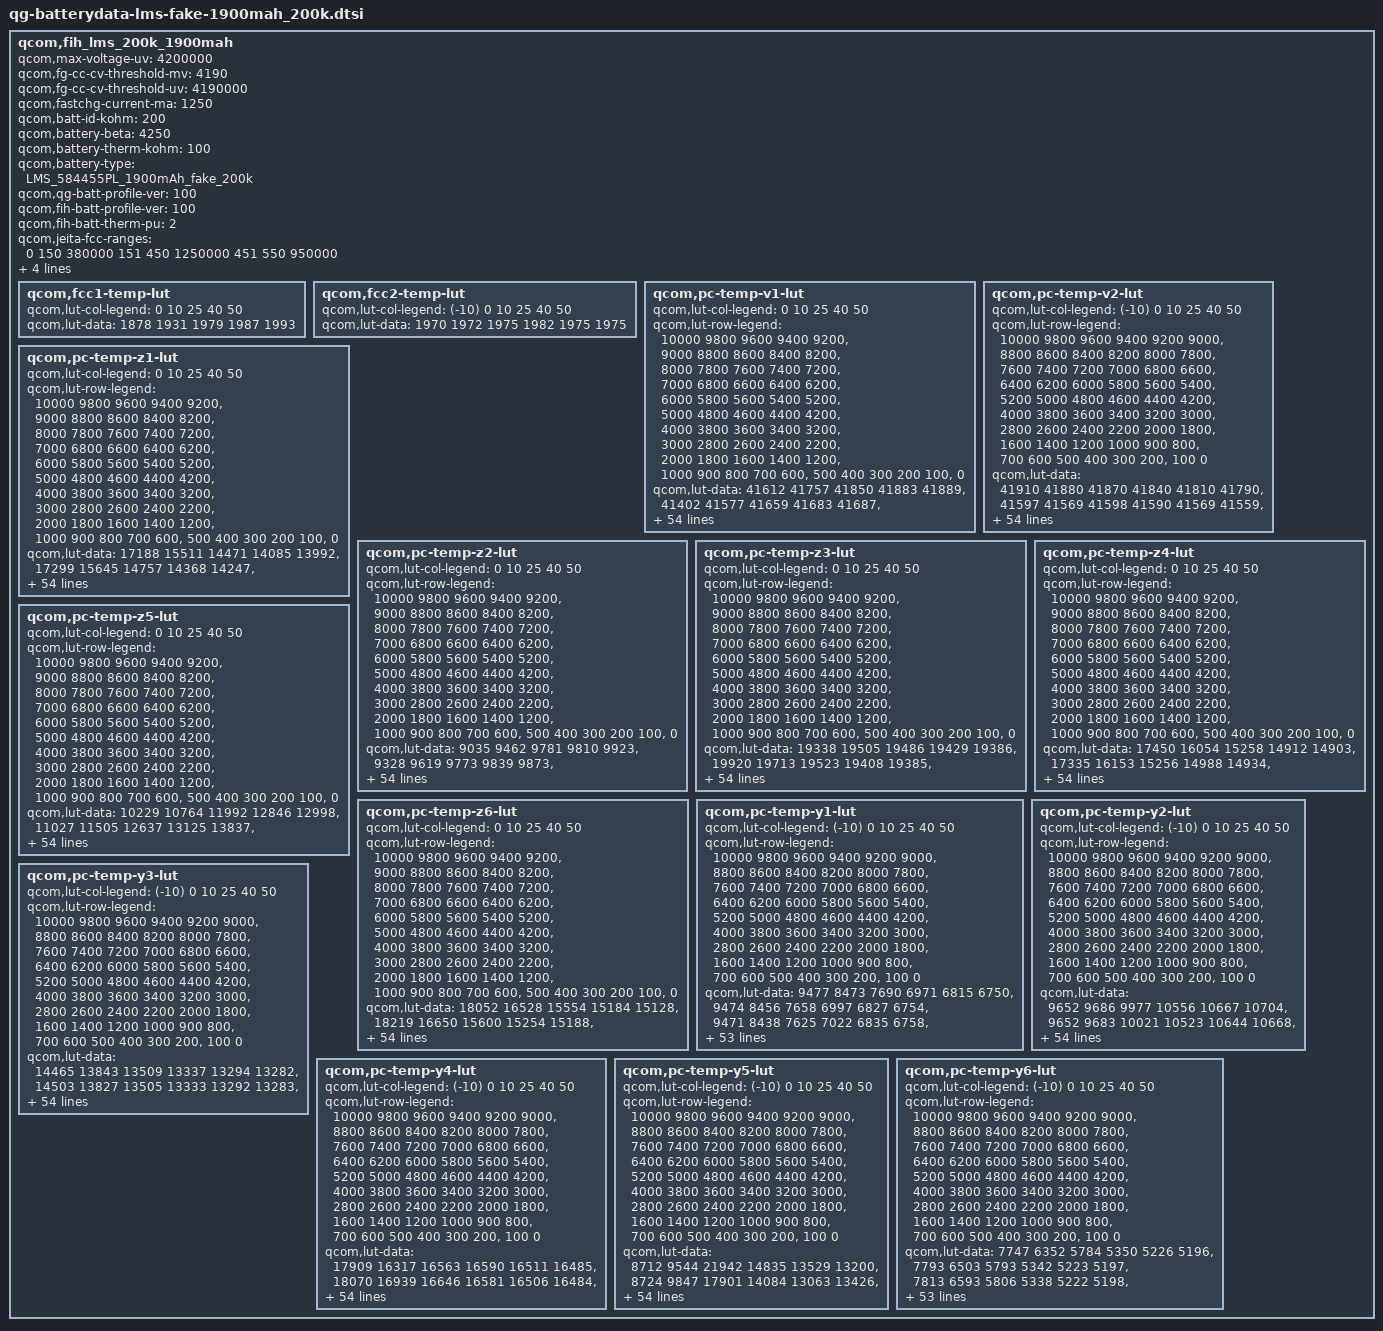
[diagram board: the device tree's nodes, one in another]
qcom,fih_lms_200k_1900mah {
	/* 3876802_FIH_LMS_VK_1900mAH_PMI632_FG_averaged_Master_Mar6th2019 */
	qcom,max-voltage-uv = <4200000>;
	qcom,fg-cc-cv-threshold-mv = <4190>;
	qcom,fg-cc-cv-threshold-uv = <4190000>;
	qcom,fastchg-current-ma = <1250>;
	qcom,batt-id-kohm = <200>;
	qcom,battery-beta = <4250>;
	qcom,battery-therm-kohm = <100>;
	qcom,battery-type =
		"LMS_584455PL_1900mAh_fake_200k";
	qcom,qg-batt-profile-ver = <100>;
	qcom,fih-batt-profile-ver = <100>;
	qcom,fih-batt-therm-pu = <2>; // pu1 = 30k, pu2 = 100k, pu3 = 400k

	qcom,jeita-fcc-ranges = <0   150   380000
				 151 450  1250000
				 451 550  950000>;
	qcom,jeita-fv-ranges =  <0   150  4200000
				 151 450  4200000
				 451 550  4000000>;

	qcom,jeita-soft-thresholds = <0x4621 0x20B8>;
	qcom,jeita-hard-thresholds = <0x58CD 0x181D>;

	qcom,fcc1-temp-lut {
		qcom,lut-col-legend = <0 10 25 40 50>;
		qcom,lut-data = <1878 1931 1979 1987 1993>;
	};

	qcom,fcc2-temp-lut {
		qcom,lut-col-legend = <(-10) 0 10 25 40 50>;
		qcom,lut-data = <1970 1972 1975 1982 1975 1975>;
	};

	qcom,pc-temp-v1-lut {
		qcom,lut-col-legend = <0 10 25 40 50>;
		qcom,lut-row-legend = <10000 9800 9600 9400 9200>,
			<9000 8800 8600 8400 8200>,
			<8000 7800 7600 7400 7200>,
			<7000 6800 6600 6400 6200>,
			<6000 5800 5600 5400 5200>,
			<5000 4800 4600 4400 4200>,
			<4000 3800 3600 3400 3200>,
			<3000 2800 2600 2400 2200>,
			<2000 1800 1600 1400 1200>,
			<1000 900 800 700 600>,
			<500 400 300 200 100>,
			<0>;
		qcom,lut-data = <41612 41757 41850 41883 41889>,
			<41402 41577 41659 41683 41687>,
			<41223 41381 41468 41482 41489>,
			<41089 41195 41272 41291 41301>,
			<40965 41046 41086 41097 41110>,
			<40763 40920 40920 40916 40923>,
			<40430 40750 40776 40753 40743>,
			<40145 40450 40605 40588 40567>,
			<39989 40158 40345 40399 40395>,
			<39869 40002 40096 40205 40226>,
			<39763 39892 39961 40042 40066>,
			<39673 39789 39865 39901 39910>,
			<39582 39692 39755 39763 39762>,
			<39478 39595 39625 39624 39620>,
			<39367 39486 39497 39491 39485>,
			<39262 39372 39380 39365 39358>,
			<39162 39267 39270 39245 39238>,
			<39066 39172 39165 39132 39124>,
			<38977 39077 39070 39032 39020>,
			<38892 38981 38952 38918 38906>,
			<38806 38879 38775 38759 38752>,
			<38719 38734 38595 38588 38581>,
			<38632 38516 38474 38451 38439>,
			<38544 38366 38377 38331 38313>,
			<38458 38313 38304 38240 38215>,
			<38379 38278 38247 38171 38142>,
			<38302 38251 38199 38114 38082>,
			<38241 38230 38154 38063 38028>,
			<38201 38210 38114 38018 37980>,
			<38172 38186 38078 37982 37939>,
			<38152 38163 38045 37953 37904>,
			<38137 38139 38018 37927 37876>,
			<38125 38113 37995 37904 37855>,
			<38113 38090 37973 37881 37835>,
			<38103 38073 37954 37858 37811>,
			<38093 38054 37935 37834 37780>,
			<38082 38032 37910 37804 37743>,
			<38069 38004 37876 37764 37698>,
			<38035 37961 37828 37712 37641>,
			<37952 37876 37753 37641 37568>,
			<37849 37766 37648 37548 37476>,
			<37720 37650 37532 37438 37368>,
			<37572 37515 37395 37305 37237>,
			<37408 37353 37247 37160 37095>,
			<37251 37211 37105 37022 36960>,
			<37109 37091 36981 36917 36860>,
			<37035 37015 36870 36845 36801>,
			<36935 36908 36691 36720 36705>,
			<36734 36601 36445 36519 36539>,
			<36281 36335 36138 36232 36261>,
			<35865 35926 35712 35810 35821>,
			<35262 35329 35133 35235 35226>,
			<34532 34619 34420 34536 34517>,
			<33625 33731 33523 33671 33641>,
			<32278 32491 32192 32472 32421>,
			<30000 30000 30000 30000 30000>;
	};

	qcom,pc-temp-v2-lut {
		qcom,lut-col-legend = <(-10) 0 10 25 40 50>;
		qcom,lut-row-legend = <10000 9800 9600 9400 9200 9000>,
			<8800 8600 8400 8200 8000 7800>,
			<7600 7400 7200 7000 6800 6600>,
			<6400 6200 6000 5800 5600 5400>,
			<5200 5000 4800 4600 4400 4200>,
			<4000 3800 3600 3400 3200 3000>,
			<2800 2600 2400 2200 2000 1800>,
			<1600 1400 1200 1000 900 800>,
			<700 600 500 400 300 200>,
			<100 0>;
		qcom,lut-data = <41910 41880 41870 41840 41810 41790>,
			<41597 41569 41598 41590 41569 41559>,
			<41330 41303 41353 41360 41345 41340>,
			<41127 41096 41144 41150 41138 41136>,
			<40971 40935 40963 40958 40946 40946>,
			<40779 40744 40780 40778 40763 40761>,
			<40487 40474 40596 40615 40592 40581>,
			<40178 40198 40402 40447 40423 40406>,
			<39929 39987 40167 40230 40247 40237>,
			<39708 39804 39912 39991 40071 40073>,
			<39524 39651 39741 39828 39911 39917>,
			<39375 39523 39635 39724 39768 39769>,
			<39234 39405 39537 39620 39631 39627>,
			<39083 39293 39432 39493 39493 39488>,
			<38933 39182 39324 39362 39361 39355>,
			<38782 39050 39199 39239 39237 39230>,
			<38630 38896 39056 39122 39118 39111>,
			<38499 38728 38903 39001 39001 38994>,
			<38394 38521 38729 38880 38890 38883>,
			<38301 38331 38557 38747 38772 38764>,
			<38214 38214 38407 38573 38607 38600>,
			<38133 38129 38272 38377 38409 38404>,
			<38057 38055 38158 38235 38262 38259>,
			<37987 37990 38060 38129 38154 38152>,
			<37921 37930 37984 38043 38067 38065>,
			<37859 37874 37933 37968 37994 37990>,
			<37801 37822 37892 37907 37932 37928>,
			<37742 37777 37860 37859 37878 37873>,
			<37683 37739 37832 37822 37829 37823>,
			<37627 37703 37807 37795 37791 37782>,
			<37574 37666 37782 37778 37762 37748>,
			<37522 37632 37759 37762 37737 37719>,
			<37471 37598 37738 37744 37714 37692>,
			<37418 37566 37716 37725 37692 37667>,
			<37365 37534 37693 37701 37661 37630>,
			<37310 37501 37665 37670 37614 37566>,
			<37250 37461 37629 37630 37556 37493>,
			<37180 37402 37573 37569 37492 37424>,
			<37100 37319 37495 37491 37418 37353>,
			<37009 37213 37400 37407 37345 37284>,
			<36905 37067 37279 37307 37271 37215>,
			<36797 36885 37139 37188 37168 37114>,
			<36683 36659 36968 37048 37037 36984>,
			<36575 36423 36745 36877 36886 36845>,
			<36471 36234 36522 36724 36760 36728>,
			<36349 36072 36320 36557 36674 36667>,
			<36269 35986 36186 36440 36589 36596>,
			<36168 35894 36028 36240 36429 36460>,
			<36020 35789 35855 35975 36185 36228>,
			<35788 35619 35631 35651 35854 35887>,
			<35402 35294 35272 35159 35387 35394>,
			<34808 34752 34708 34521 34780 34766>,
			<33991 34008 33971 33727 34053 34029>,
			<32892 32962 33011 32716 33144 33125>,
			<31287 31346 31633 31443 31990 31977>,
			<27080 26927 29600 27318 29739 29453>;
	};

	qcom,pc-temp-z1-lut {
		qcom,lut-col-legend = <0 10 25 40 50>;
		qcom,lut-row-legend = <10000 9800 9600 9400 9200>,
			<9000 8800 8600 8400 8200>,
			<8000 7800 7600 7400 7200>,
			<7000 6800 6600 6400 6200>,
			<6000 5800 5600 5400 5200>,
			<5000 4800 4600 4400 4200>,
			<4000 3800 3600 3400 3200>,
			<3000 2800 2600 2400 2200>,
			<2000 1800 1600 1400 1200>,
			<1000 900 800 700 600>,
			<500 400 300 200 100>,
			<0>;
		qcom,lut-data = <17188 15511 14471 14085 13992>,
			<17299 15645 14757 14368 14247>,
			<17367 15708 14803 14424 14306>,
			<17396 15762 14818 14447 14323>,
			<17415 15788 14837 14458 14348>,
			<17427 15805 14844 14470 14366>,
			<17437 15809 14847 14486 14376>,
			<17441 15791 14848 14499 14385>,
			<17423 15772 14847 14507 14398>,
			<17391 15774 14847 14513 14411>,
			<17384 15782 14855 14520 14420>,
			<17395 15789 14878 14527 14427>,
			<17412 15796 14894 14533 14433>,
			<17439 15805 14903 14541 14438>,
			<17473 15828 14911 14548 14442>,
			<17479 15862 14918 14553 14447>,
			<17450 15875 14925 14558 14454>,
			<17425 15879 14940 14564 14461>,
			<17456 15881 14966 14576 14468>,
			<17523 15872 14977 14585 14474>,
			<17539 15856 14969 14587 14481>,
			<17478 15858 14960 14588 14487>,
			<17421 15883 14962 14592 14493>,
			<17418 15898 14968 14603 14500>,
			<17419 15897 14978 14613 14506>,
			<17421 15895 14999 14624 14512>,
			<17424 15897 15015 14631 14518>,
			<17430 15906 15018 14631 14523>,
			<17459 15915 15020 14631 14529>,
			<17522 15922 15019 14634 14535>,
			<17545 15930 15015 14645 14542>,
			<17501 15939 15012 14652 14546>,
			<17453 15949 15014 14652 14548>,
			<17475 15963 15018 14652 14550>,
			<17558 15990 15034 14656 14553>,
			<17596 16015 15064 14666 14558>,
			<17573 16023 15071 14672 14562>,
			<17544 16028 15058 14674 14565>,
			<17558 16038 15048 14676 14568>,
			<17620 16078 15054 14680 14574>,
			<17653 16114 15064 14686 14581>,
			<17651 16120 15071 14696 14586>,
			<17647 16123 15076 14709 14589>,
			<17571 16147 15082 14710 14594>,
			<17552 16145 15094 14710 14601>,
			<17669 16126 15127 14723 14612>,
			<17558 16126 15140 14735 14620>,
			<17555 16147 15125 14745 14635>,
			<17671 16166 15128 14763 14660>,
			<17746 16216 15140 14798 14703>,
			<17639 16221 15194 14849 14778>,
			<17617 16271 15258 14900 14836>,
			<17753 16287 15255 14969 14902>,
			<17774 16314 15350 15049 14977>,
			<17774 16314 15350 15049 14977>,
			<17774 16314 15350 15049 14977>;
	};

	qcom,pc-temp-z2-lut {
		qcom,lut-col-legend = <0 10 25 40 50>;
		qcom,lut-row-legend = <10000 9800 9600 9400 9200>,
			<9000 8800 8600 8400 8200>,
			<8000 7800 7600 7400 7200>,
			<7000 6800 6600 6400 6200>,
			<6000 5800 5600 5400 5200>,
			<5000 4800 4600 4400 4200>,
			<4000 3800 3600 3400 3200>,
			<3000 2800 2600 2400 2200>,
			<2000 1800 1600 1400 1200>,
			<1000 900 800 700 600>,
			<500 400 300 200 100>,
			<0>;
		qcom,lut-data = <9035 9462 9781 9810 9923>,
			<9328 9619 9773 9839 9873>,
			<9463 9616 9773 9863 9945>,
			<9463 9612 9780 9914 9902>,
			<9462 9608 9782 9910 9902>,
			<9459 9605 9783 9904 9900>,
			<9448 9600 9783 9884 9875>,
			<9441 9591 9783 9870 9852>,
			<9443 9585 9780 9882 9861>,
			<9447 9585 9776 9900 9883>,
			<9448 9587 9776 9893 9901>,
			<9447 9589 9777 9854 9917>,
			<9445 9591 9782 9837 9924>,
			<9442 9595 9803 9851 9923>,
			<9439 9603 9826 9871 9921>,
			<9438 9618 9838 9890 9920>,
			<9440 9632 9848 9909 9918>,
			<9442 9646 9859 9912 9918>,
			<9446 9663 9869 9903 9921>,
			<9453 9691 9881 9898 9927>,
			<9463 9722 9901 9950 9999>,
			<9479 9733 9915 10025 10105>,
			<9497 9735 9909 10038 10118>,
			<9515 9739 9891 10042 10103>,
			<9532 9755 9880 10040 10078>,
			<9548 9773 9876 9997 10004>,
			<9564 9777 9872 9950 9929>,
			<9577 9777 9863 9930 9908>,
			<9583 9777 9854 9916 9896>,
			<9587 9771 9853 9915 9882>,
			<9591 9764 9858 9917 9864>,
			<9594 9764 9865 9922 9856>,
			<9598 9767 9880 9949 9875>,
			<9606 9771 9899 9986 9911>,
			<9619 9775 9914 10006 9942>,
			<9619 9780 9927 10021 9973>,
			<9435 9786 9936 10027 9995>,
			<9216 9792 9942 10029 10012>,
			<9200 9797 9948 10031 10023>,
			<9235 9802 9959 10042 10027>,
			<9253 9804 9970 10059 10030>,
			<9246 9799 9971 10064 10039>,
			<9237 9790 9968 10065 10058>,
			<9230 9795 9972 10058 10059>,
			<9214 9729 9991 10049 10052>,
			<9181 9597 9989 10098 10056>,
			<9167 9711 9969 10063 10048>,
			<9136 9494 9945 9986 10023>,
			<9247 9761 9906 9945 9949>,
			<9713 9821 9819 9861 9831>,
			<9717 9867 9661 9731 9683>,
			<9644 9833 9530 9608 9662>,
			<9565 9682 9442 9716 9713>,
			<9104 9519 9260 9774 9761>,
			<9104 9519 9260 9774 9761>,
			<9104 9519 9260 9774 9761>;
	};

	qcom,pc-temp-z3-lut {
		qcom,lut-col-legend = <0 10 25 40 50>;
		qcom,lut-row-legend = <10000 9800 9600 9400 9200>,
			<9000 8800 8600 8400 8200>,
			<8000 7800 7600 7400 7200>,
			<7000 6800 6600 6400 6200>,
			<6000 5800 5600 5400 5200>,
			<5000 4800 4600 4400 4200>,
			<4000 3800 3600 3400 3200>,
			<3000 2800 2600 2400 2200>,
			<2000 1800 1600 1400 1200>,
			<1000 900 800 700 600>,
			<500 400 300 200 100>,
			<0>;
		qcom,lut-data = <19338 19505 19486 19429 19386>,
			<19920 19713 19523 19408 19385>,
			<20217 19845 19573 19446 19399>,
			<20257 19912 19616 19460 19411>,
			<20279 19912 19635 19473 19418>,
			<20314 19898 19632 19475 19420>,
			<20364 19894 19613 19463 19419>,
			<20391 19928 19604 19455 19417>,
			<20367 19962 19621 19461 19414>,
			<20314 19946 19640 19471 19412>,
			<20262 19892 19625 19468 19410>,
			<20200 19845 19587 19450 19408>,
			<20158 19800 19575 19440 19407>,
			<20146 19773 19576 19438 19406>,
			<20140 19780 19576 19437 19405>,
			<20130 19793 19571 19437 19401>,
			<20118 19795 19562 19436 19394>,
			<20104 19781 19558 19435 19388>,
			<20082 19770 19557 19431 19382>,
			<20058 19772 19557 19429 19380>,
			<20053 19777 19580 19444 19392>,
			<20082 19787 19604 19466 19416>,
			<20115 19807 19598 19469 19432>,
			<20130 19819 19581 19470 19444>,
			<20141 19814 19579 19473 19454>,
			<20144 19805 19605 19496 19463>,
			<20140 19798 19624 19517 19468>,
			<20134 19791 19624 19515 19465>,
			<20124 19785 19623 19507 19457>,
			<20107 19780 19620 19497 19449>,
			<20086 19777 19610 19482 19441>,
			<20062 19777 19601 19470 19433>,
			<20033 19777 19592 19466 19423>,
			<20005 19777 19583 19462 19414>,
			<19976 19772 19575 19456 19405>,
			<19920 19763 19567 19447 19398>,
			<19637 19751 19561 19444 19396>,
			<19329 19734 19557 19444 19396>,
			<19287 19722 19552 19443 19396>,
			<19282 19716 19546 19434 19396>,
			<19281 19710 19539 19420 19395>,
			<19281 19696 19534 19417 19392>,
			<19282 19679 19530 19418 19385>,
			<19282 19670 19525 19418 19382>,
			<19283 19527 19509 19412 19381>,
			<19287 19267 19475 19390 19379>,
			<19289 19264 19497 19396 19380>,
			<19304 19268 19514 19406 19378>,
			<19685 19657 19559 19446 19398>,
			<19871 19687 19635 19496 19451>,
			<19864 19758 19687 19505 19455>,
			<19891 19895 19696 19496 19451>,
			<19897 20034 19695 19493 19443>,
			<19806 20187 19645 19490 19441>,
			<19806 20187 19645 19490 19441>,
			<19806 20187 19645 19490 19441>;
	};

	qcom,pc-temp-z4-lut {
		qcom,lut-col-legend = <0 10 25 40 50>;
		qcom,lut-row-legend = <10000 9800 9600 9400 9200>,
			<9000 8800 8600 8400 8200>,
			<8000 7800 7600 7400 7200>,
			<7000 6800 6600 6400 6200>,
			<6000 5800 5600 5400 5200>,
			<5000 4800 4600 4400 4200>,
			<4000 3800 3600 3400 3200>,
			<3000 2800 2600 2400 2200>,
			<2000 1800 1600 1400 1200>,
			<1000 900 800 700 600>,
			<500 400 300 200 100>,
			<0>;
		qcom,lut-data = <17450 16054 15258 14912 14903>,
			<17335 16153 15256 14988 14934>,
			<17183 16066 15316 14995 14916>,
			<16973 15915 15285 15026 14966>,
			<16727 15755 15205 14973 14929>,
			<16507 15562 15121 14927 14895>,
			<16303 15433 15021 14889 14869>,
			<16118 15364 14966 14857 14845>,
			<15950 15305 14951 14833 14821>,
			<15801 15230 14939 14815 14799>,
			<15700 15150 14908 14801 14783>,
			<15629 15099 14862 14791 14770>,
			<15569 15070 14836 14781 14760>,
			<15507 15044 14823 14771 14749>,
			<15451 15010 14815 14762 14740>,
			<15403 14974 14813 14753 14734>,
			<15362 14949 14811 14745 14729>,
			<15326 14932 14807 14740 14724>,
			<15295 14919 14800 14736 14721>,
			<15268 14908 14800 14734 14719>,
			<15234 14900 14888 14785 14761>,
			<15181 14934 14998 14867 14833>,
			<15143 15128 15046 14910 14859>,
			<15143 15250 15079 14939 14872>,
			<15151 15235 15079 14945 14874>,
			<15161 15202 15022 14894 14841>,
			<15182 15165 14963 14840 14802>,
			<15199 15119 14932 14825 14788>,
			<15196 15076 14908 14815 14780>,
			<15181 15039 14895 14808 14773>,
			<15165 15007 14886 14802 14767>,
			<15144 14978 14881 14796 14762>,
			<15124 14953 14878 14787 14753>,
			<15109 14932 14875 14779 14745>,
			<15097 14916 14871 14780 14747>,
			<15100 14903 14866 14783 14756>,
			<15345 14892 14865 14785 14761>,
			<15637 14882 14865 14786 14762>,
			<15663 14880 14865 14787 14763>,
			<15627 14882 14863 14791 14761>,
			<15596 14884 14858 14798 14755>,
			<15580 14880 14852 14796 14753>,
			<15561 14870 14841 14786 14751>,
			<15528 14850 14825 14782 14753>,
			<15393 14936 14795 14777 14753>,
			<15331 15122 14741 14737 14713>,
			<15334 15122 14741 14728 14705>,
			<15333 15148 14800 14742 14715>,
			<15112 15002 14878 14769 14738>,
			<15260 15137 14927 14805 14762>,
			<15444 15218 14914 14805 14770>,
			<15564 15204 14895 14798 14763>,
			<15790 15159 14881 14779 14753>,
			<16077 15088 14902 14767 14746>,
			<16077 15088 14902 14767 14746>,
			<16077 15088 14902 14767 14746>;
	};

	qcom,pc-temp-z5-lut {
		qcom,lut-col-legend = <0 10 25 40 50>;
		qcom,lut-row-legend = <10000 9800 9600 9400 9200>,
			<9000 8800 8600 8400 8200>,
			<8000 7800 7600 7400 7200>,
			<7000 6800 6600 6400 6200>,
			<6000 5800 5600 5400 5200>,
			<5000 4800 4600 4400 4200>,
			<4000 3800 3600 3400 3200>,
			<3000 2800 2600 2400 2200>,
			<2000 1800 1600 1400 1200>,
			<1000 900 800 700 600>,
			<500 400 300 200 100>,
			<0>;
		qcom,lut-data = <10229 10764 11992 12846 12998>,
			<11027 11505 12637 13125 13837>,
			<11488 12191 13112 14460 14710>,
			<11622 12664 13914 14404 14376>,
			<11708 12881 14382 15078 14768>,
			<11843 12999 14627 15264 15011>,
			<12040 13227 14753 15096 15082>,
			<12200 14011 14990 14971 15159>,
			<12297 14693 16132 15659 15380>,
			<12366 14650 17227 16729 15751>,
			<12361 14420 17014 16767 16123>,
			<12237 14196 16342 16298 16517>,
			<12142 13945 16261 16093 16926>,
			<12215 13788 17289 16349 17452>,
			<12395 14325 18128 16781 17849>,
			<12568 15560 18232 17320 17759>,
			<12740 16277 18299 17981 17434>,
			<12919 16581 18540 18375 17313>,
			<13072 16988 19265 18560 17296>,
			<13230 18228 20425 18840 17290>,
			<13569 20278 23731 20282 18628>,
			<14729 22498 26693 21975 20751>,
			<16268 25316 24531 20953 20282>,
			<17794 26723 18914 16942 17103>,
			<19438 24975 17328 15419 15676>,
			<20679 22036 17927 16807 16582>,
			<21720 20422 18764 18535 17817>,
			<22353 19292 19758 19664 18578>,
			<22164 18790 20849 20552 19210>,
			<21383 18673 21643 20634 19779>,
			<20512 18614 22312 20211 20359>,
			<19549 18883 22574 19975 20621>,
			<18513 19851 22611 20628 20503>,
			<17607 20553 22627 21429 20242>,
			<16771 20944 22497 21271 19794>,
			<15624 21172 22089 20503 19011>,
			<13118 21062 21636 19858 18386>,
			<10803 20674 21087 19440 17950>,
			<10514 20325 20516 18930 17571>,
			<10492 20088 19950 17700 17248>,
			<10486 19775 19426 16244 16937>,
			<10502 18760 19054 15936 16421>,
			<10514 17586 18786 15899 15620>,
			<10491 17776 18827 15806 14972>,
			<10535 15534 18776 15561 14751>,
			<10553 10709 18387 15598 16249>,
			<10546 10678 23110 16831 17594>,
			<10575 10702 21725 17703 17276>,
			<13916 25367 20486 19572 18102>,
			<25814 19934 20596 20127 20227>,
			<18380 17342 20042 19010 18132>,
			<14961 17048 18322 18014 17879>,
			<13112 16530 17702 19463 18227>,
			<11299 16430 14739 20603 19041>,
			<11299 16430 14739 20603 19041>,
			<11299 16430 14739 20603 19041>;
	};

	qcom,pc-temp-z6-lut {
		qcom,lut-col-legend = <0 10 25 40 50>;
		qcom,lut-row-legend = <10000 9800 9600 9400 9200>,
			<9000 8800 8600 8400 8200>,
			<8000 7800 7600 7400 7200>,
			<7000 6800 6600 6400 6200>,
			<6000 5800 5600 5400 5200>,
			<5000 4800 4600 4400 4200>,
			<4000 3800 3600 3400 3200>,
			<3000 2800 2600 2400 2200>,
			<2000 1800 1600 1400 1200>,
			<1000 900 800 700 600>,
			<500 400 300 200 100>,
			<0>;
		qcom,lut-data = <18052 16528 15554 15184 15128>,
			<18219 16650 15600 15254 15188>,
			<18277 16636 15655 15287 15200>,
			<18195 16606 15652 15306 15225>,
			<18033 16544 15635 15294 15218>,
			<17892 16422 15603 15278 15210>,
			<17757 16333 15539 15255 15200>,
			<17629 16286 15506 15239 15190>,
			<17509 16243 15501 15235 15181>,
			<17400 16185 15498 15233 15172>,
			<17319 16118 15478 15226 15165>,
			<17258 16068 15442 15213 15160>,
			<17208 16030 15429 15204 15155>,
			<17166 16003 15427 15200 15151>,
			<17131 15990 15426 15197 15146>,
			<17099 15981 15423 15194 15142>,
			<17070 15968 15420 15191 15137>,
			<17041 15948 15419 15189 15133>,
			<17003 15937 15418 15187 15129>,
			<16965 15937 15419 15186 15128>,
			<16951 15938 15471 15216 15153>,
			<16948 15957 15532 15264 15198>,
			<16947 16054 15550 15288 15222>,
			<16951 16115 15560 15305 15239>,
			<16961 16108 15561 15309 15244>,
			<16964 16093 15553 15302 15235>,
			<16964 16077 15543 15292 15224>,
			<16964 16056 15533 15285 15216>,
			<16959 16038 15524 15277 15209>,
			<16944 16024 15516 15269 15202>,
			<16926 16012 15509 15259 15196>,
			<16902 16003 15503 15251 15189>,
			<16876 15996 15498 15245 15179>,
			<16856 15991 15494 15240 15171>,
			<16839 15987 15490 15237 15169>,
			<16820 15983 15487 15235 15169>,
			<16795 15978 15486 15234 15169>,
			<16771 15973 15486 15235 15170>,
			<16754 15972 15486 15236 15172>,
			<16740 15981 15485 15235 15171>,
			<16733 15989 15482 15232 15169>,
			<16731 15987 15480 15229 15167>,
			<16730 15984 15479 15227 15164>,
			<16732 15988 15475 15227 15165>,
			<16707 15977 15462 15224 15165>,
			<16708 15956 15439 15200 15148>,
			<16722 15972 15458 15201 15147>,
			<16742 16002 15510 15220 15153>,
			<16833 16146 15588 15266 15183>,
			<17045 16242 15675 15329 15236>,
			<17133 16337 15731 15366 15266>,
			<17224 16427 15770 15390 15284>,
			<17338 16515 15814 15412 15299>,
			<17433 16604 15852 15437 15316>,
			<17433 16604 15852 15437 15316>,
			<17433 16604 15852 15437 15316>;
	};

	qcom,pc-temp-y1-lut {
		qcom,lut-col-legend = <(-10) 0 10 25 40 50>;
		qcom,lut-row-legend = <10000 9800 9600 9400 9200 9000>,
			<8800 8600 8400 8200 8000 7800>,
			<7600 7400 7200 7000 6800 6600>,
			<6400 6200 6000 5800 5600 5400>,
			<5200 5000 4800 4600 4400 4200>,
			<4000 3800 3600 3400 3200 3000>,
			<2800 2600 2400 2200 2000 1800>,
			<1600 1400 1200 1000 900 800>,
			<700 600 500 400 300 200>,
			<100 0>;
		qcom,lut-data = <9477 8473 7690 6971 6815 6750>,
			<9474 8456 7658 6997 6827 6754>,
			<9471 8438 7625 7022 6835 6758>,
			<9468 8421 7596 7042 6841 6762>,
			<9465 8407 7576 7055 6843 6765>,
			<9464 8398 7571 7059 6844 6767>,
			<9463 8391 7578 7051 6840 6769>,
			<9463 8387 7587 7044 6836 6771>,
			<9466 8388 7592 7048 6840 6771>,
			<9479 8393 7597 7058 6853 6771>,
			<9501 8405 7605 7064 6856 6771>,
			<9556 8444 7625 7066 6856 6772>,
			<9593 8471 7638 7069 6856 6774>,
			<9581 8450 7631 7080 6857 6776>,
			<9554 8414 7621 7092 6858 6778>,
			<9529 8402 7623 7092 6859 6779>,
			<9502 8397 7636 7090 6862 6781>,
			<9492 8396 7645 7090 6864 6784>,
			<9561 8413 7647 7095 6865 6787>,
			<9639 8432 7649 7101 6865 6790>,
			<9634 8430 7655 7098 6868 6792>,
			<9599 8421 7662 7091 6874 6793>,
			<9561 8416 7663 7090 6878 6795>,
			<9513 8413 7652 7093 6880 6800>,
			<9483 8411 7642 7097 6882 6805>,
			<9482 8435 7637 7106 6886 6808>,
			<9482 8477 7633 7117 6889 6811>,
			<9488 8477 7634 7125 6890 6814>,
			<9517 8440 7640 7131 6890 6816>,
			<9534 8420 7643 7134 6890 6819>,
			<9515 8447 7638 7136 6894 6825>,
			<9490 8478 7633 7139 6899 6830>,
			<9489 8471 7633 7142 6902 6831>,
			<9491 8445 7635 7145 6904 6832>,
			<9498 8439 7636 7143 6907 6832>,
			<9539 8470 7638 7130 6909 6833>,
			<9588 8497 7641 7122 6912 6835>,
			<9623 8482 7653 7128 6914 6839>,
			<9651 8455 7672 7137 6916 6844>,
			<9636 8450 7681 7139 6921 6847>,
			<9529 8458 7686 7141 6929 6849>,
			<9512 8470 7685 7146 6933 6854>,
			<9548 8489 7684 7154 6936 6864>,
			<9637 8543 7722 7192 6951 6871>,
			<9675 8576 7727 7175 6968 6879>,
			<9760 8592 7742 7189 6976 6893>,
			<9759 8599 7779 7192 6991 6908>,
			<9788 8621 7756 7211 7007 6934>,
			<9801 8628 7755 7221 7025 6962>,
			<9810 8642 7765 7220 7058 7005>,
			<9861 8705 7788 7262 7073 7022>,
			<9995 8728 7828 7261 7106 7043>,
			<10199 8763 7861 7329 7113 7070>,
			<10461 8929 7960 7367 7156 7107>,
			<10461 8929 7960 7367 7156 7107>,
			<10461 8929 7960 7367 7156 7107>;
	};

	qcom,pc-temp-y2-lut {
		qcom,lut-col-legend = <(-10) 0 10 25 40 50>;
		qcom,lut-row-legend = <10000 9800 9600 9400 9200 9000>,
			<8800 8600 8400 8200 8000 7800>,
			<7600 7400 7200 7000 6800 6600>,
			<6400 6200 6000 5800 5600 5400>,
			<5200 5000 4800 4600 4400 4200>,
			<4000 3800 3600 3400 3200 3000>,
			<2800 2600 2400 2200 2000 1800>,
			<1600 1400 1200 1000 900 800>,
			<700 600 500 400 300 200>,
			<100 0>;
		qcom,lut-data = <9652 9686 9977 10556 10667 10704>,
			<9652 9683 10021 10523 10644 10668>,
			<9653 9680 10072 10486 10619 10624>,
			<9653 9677 10121 10449 10593 10581>,
			<9653 9675 10161 10420 10566 10550>,
			<9653 9674 10183 10404 10537 10541>,
			<9653 9673 10197 10396 10499 10549>,
			<9653 9673 10205 10390 10471 10557>,
			<9653 9671 10204 10379 10472 10554>,
			<9653 9668 10201 10366 10475 10543>,
			<9653 9665 10204 10359 10476 10528>,
			<9653 9663 10241 10354 10470 10504>,
			<9653 9662 10287 10352 10466 10488>,
			<9653 9663 10323 10364 10472 10485>,
			<9654 9663 10360 10390 10487 10484>,
			<9654 9663 10402 10420 10501 10493>,
			<9654 9663 10451 10461 10517 10536>,
			<9654 9663 10470 10505 10541 10582>,
			<9654 9662 10461 10561 10602 10638>,
			<9654 9661 10446 10598 10661 10677>,
			<9654 9660 10428 10595 10678 10671>,
			<9654 9660 10406 10587 10687 10651>,
			<9654 9660 10393 10586 10693 10645>,
			<9654 9659 10387 10598 10696 10652>,
			<9653 9659 10382 10611 10700 10663>,
			<9654 9658 10375 10621 10709 10694>,
			<9654 9658 10369 10630 10719 10737>,
			<9654 9658 10365 10640 10724 10758>,
			<9654 9658 10362 10652 10727 10770>,
			<9654 9658 10357 10655 10732 10783>,
			<9654 9658 10349 10646 10775 10798>,
			<9653 9657 10341 10634 10819 10816>,
			<9653 9657 10339 10620 10808 10852>,
			<9653 9656 10338 10604 10771 10904>,
			<9653 9656 10336 10601 10754 10909>,
			<9653 9656 10333 10602 10752 10804>,
			<9653 9655 10325 10602 10748 10723>,
			<9653 9655 10123 10595 10733 10731>,
			<9653 9655 9788 10583 10714 10751>,
			<9653 9654 9710 10568 10716 10766>,
			<9653 9654 9698 10551 10739 10778>,
			<9653 9654 9685 10541 10727 10748>,
			<9653 9653 9673 10527 10699 10700>,
			<9652 9653 9666 10476 10690 10736>,
			<9653 9653 9663 10414 10648 10646>,
			<9652 9653 9661 10369 10588 10577>,
			<9652 9653 9660 10410 10574 10508>,
			<9652 9652 9659 10395 10494 10459>,
			<9651 9652 9658 10367 10504 10452>,
			<9651 9652 9657 10392 10508 10458>,
			<9650 9652 9657 10086 10537 10511>,
			<9649 9651 9656 10038 10556 10554>,
			<9648 9651 9655 9954 10576 10565>,
			<9647 9649 9654 10016 10540 10539>,
			<9647 9649 9654 10016 10540 10539>,
			<9647 9649 9654 10016 10540 10539>;
	};

	qcom,pc-temp-y3-lut {
		qcom,lut-col-legend = <(-10) 0 10 25 40 50>;
		qcom,lut-row-legend = <10000 9800 9600 9400 9200 9000>,
			<8800 8600 8400 8200 8000 7800>,
			<7600 7400 7200 7000 6800 6600>,
			<6400 6200 6000 5800 5600 5400>,
			<5200 5000 4800 4600 4400 4200>,
			<4000 3800 3600 3400 3200 3000>,
			<2800 2600 2400 2200 2000 1800>,
			<1600 1400 1200 1000 900 800>,
			<700 600 500 400 300 200>,
			<100 0>;
		qcom,lut-data = <14465 13843 13509 13337 13294 13282>,
			<14503 13827 13505 13333 13292 13283>,
			<14517 13797 13498 13331 13292 13285>,
			<14513 13764 13490 13332 13292 13286>,
			<14496 13739 13484 13334 13292 13287>,
			<14473 13731 13481 13337 13294 13288>,
			<14432 13733 13481 13344 13298 13289>,
			<14385 13735 13481 13349 13303 13290>,
			<14347 13716 13472 13346 13304 13290>,
			<14315 13672 13451 13340 13305 13290>,
			<14310 13659 13446 13340 13306 13291>,
			<14335 13665 13454 13350 13306 13296>,
			<14354 13674 13460 13359 13306 13300>,
			<14348 13690 13459 13362 13308 13300>,
			<14334 13708 13456 13365 13312 13300>,
			<14315 13712 13452 13365 13315 13302>,
			<14286 13714 13446 13364 13318 13305>,
			<14272 13714 13436 13362 13319 13307>,
			<14271 13680 13416 13360 13320 13307>,
			<14270 13642 13399 13358 13320 13307>,
			<14273 13643 13396 13350 13317 13304>,
			<14283 13656 13396 13337 13309 13296>,
			<14298 13670 13394 13330 13304 13292>,
			<14322 13689 13385 13326 13300 13289>,
			<14347 13708 13379 13324 13298 13288>,
			<14363 13719 13380 13324 13298 13287>,
			<14377 13729 13385 13324 13297 13287>,
			<14391 13748 13390 13324 13297 13287>,
			<14405 13786 13397 13324 13297 13288>,
			<14420 13824 13404 13325 13297 13289>,
			<14441 13854 13409 13329 13298 13289>,
			<14464 13884 13413 13333 13300 13289>,
			<14482 13919 13419 13336 13300 13290>,
			<14498 13957 13426 13338 13300 13294>,
			<14518 13996 13432 13341 13301 13295>,
			<14544 14034 13438 13344 13302 13293>,
			<14571 14073 13445 13347 13303 13292>,
			<14595 14111 13462 13349 13303 13292>,
			<14619 14150 13487 13351 13302 13293>,
			<14648 14194 13507 13352 13304 13295>,
			<14682 14242 13525 13354 13310 13300>,
			<14723 14285 13548 13358 13312 13299>,
			<14773 14313 13575 13363 13313 13296>,
			<14829 14314 13582 13355 13310 13299>,
			<14904 14366 13597 13360 13310 13294>,
			<15112 14479 13656 13365 13320 13307>,
			<15245 14532 13669 13372 13328 13310>,
			<15411 14599 13686 13367 13327 13312>,
			<15610 14699 13718 13360 13327 13314>,
			<15917 14793 13760 13360 13325 13314>,
			<16464 14909 13798 13344 13318 13309>,
			<17846 15084 13866 13349 13318 13307>,
			<20651 15381 13970 13359 13322 13311>,
			<25020 16227 14147 13391 13327 13316>,
			<25020 16227 14147 13391 13327 13316>,
			<25020 16227 14147 13391 13327 13316>;
	};

	qcom,pc-temp-y4-lut {
		qcom,lut-col-legend = <(-10) 0 10 25 40 50>;
		qcom,lut-row-legend = <10000 9800 9600 9400 9200 9000>,
			<8800 8600 8400 8200 8000 7800>,
			<7600 7400 7200 7000 6800 6600>,
			<6400 6200 6000 5800 5600 5400>,
			<5200 5000 4800 4600 4400 4200>,
			<4000 3800 3600 3400 3200 3000>,
			<2800 2600 2400 2200 2000 1800>,
			<1600 1400 1200 1000 900 800>,
			<700 600 500 400 300 200>,
			<100 0>;
		qcom,lut-data = <17909 16317 16563 16590 16511 16485>,
			<18070 16939 16646 16581 16506 16484>,
			<18165 17379 16756 16577 16504 16484>,
			<18212 17662 16870 16578 16505 16484>,
			<18228 17808 16960 16581 16506 16484>,
			<18222 17834 17003 16587 16509 16485>,
			<18008 17631 17021 16609 16514 16486>,
			<17746 17420 17030 16629 16519 16488>,
			<17656 17420 16994 16621 16520 16491>,
			<17603 17456 16911 16602 16521 16497>,
			<17560 17491 16897 16600 16523 16500>,
			<17528 17532 16980 16626 16530 16501>,
			<17492 17555 17068 16653 16538 16503>,
			<17429 17539 17123 16667 16546 16510>,
			<17354 17499 17163 16682 16556 16523>,
			<17292 17439 17161 16714 16571 16536>,
			<17236 17332 17128 16768 16594 16551>,
			<17215 17224 17082 16809 16625 16572>,
			<17217 17109 17008 16839 16680 16620>,
			<17220 17029 16918 16855 16724 16660>,
			<17223 17029 16829 16797 16687 16632>,
			<17226 17046 16739 16669 16584 16553>,
			<17228 17063 16702 16612 16532 16511>,
			<17229 17078 16688 16589 16509 16491>,
			<17229 17098 16682 16575 16499 16482>,
			<17230 17135 16696 16564 16500 16482>,
			<17232 17176 16727 16557 16502 16485>,
			<17235 17183 16758 16561 16506 16488>,
			<17242 17183 16793 16576 16512 16494>,
			<17250 17183 16831 16595 16521 16502>,
			<17257 17199 16872 16624 16532 16513>,
			<17264 17229 16917 16656 16546 16526>,
			<17271 17259 16967 16690 16565 16540>,
			<17279 17294 17022 16726 16586 16554>,
			<17284 17334 17078 16759 16591 16556>,
			<17286 17385 17138 16792 16584 16536>,
			<17287 17423 17195 16818 16578 16521>,
			<17280 17437 17255 16833 16578 16521>,
			<17261 17446 17305 16847 16579 16522>,
			<17239 17433 17309 16866 16585 16528>,
			<17211 17346 17286 16888 16608 16547>,
			<17188 17233 17255 16907 16619 16550>,
			<17171 17102 17197 16909 16626 16550>,
			<17150 16995 17000 16760 16610 16540>,
			<17105 16913 16901 16770 16594 16526>,
			<17133 16905 16896 16789 16634 16563>,
			<17167 16920 16884 16809 16639 16575>,
			<17211 16941 16876 16784 16636 16575>,
			<17260 16965 16887 16764 16635 16576>,
			<17266 16997 16889 16741 16628 16572>,
			<17289 16980 16858 16692 16592 16553>,
			<17543 16959 16808 16687 16592 16555>,
			<18259 16972 16817 16720 16623 16590>,
			<20083 17203 16888 16884 16725 16709>,
			<20083 17203 16888 16884 16725 16709>,
			<20083 17203 16888 16884 16725 16709>;
	};

	qcom,pc-temp-y5-lut {
		qcom,lut-col-legend = <(-10) 0 10 25 40 50>;
		qcom,lut-row-legend = <10000 9800 9600 9400 9200 9000>,
			<8800 8600 8400 8200 8000 7800>,
			<7600 7400 7200 7000 6800 6600>,
			<6400 6200 6000 5800 5600 5400>,
			<5200 5000 4800 4600 4400 4200>,
			<4000 3800 3600 3400 3200 3000>,
			<2800 2600 2400 2200 2000 1800>,
			<1600 1400 1200 1000 900 800>,
			<700 600 500 400 300 200>,
			<100 0>;
		qcom,lut-data = <8712 9544 21942 14835 13529 13200>,
			<8724 9847 17901 14084 13063 13426>,
			<9581 10142 14926 13595 12788 13573>,
			<10588 10429 12938 13316 12653 13656>,
			<11388 10708 11859 13191 12608 13694>,
			<11647 10983 11650 13180 12623 13699>,
			<11653 11317 12959 13441 13147 13652>,
			<11656 11544 14296 13696 13683 13561>,
			<11565 11413 13668 13330 13636 13346>,
			<11344 11074 12056 12509 13421 13011>,
			<11352 11008 11629 12352 13205 13004>,
			<12005 11343 11900 12712 12963 13645>,
			<12550 11852 12300 12948 12774 14104>,
			<12642 12580 12813 12910 12672 13750>,
			<12692 13493 13478 12832 12599 13180>,
			<12537 14261 14281 12741 12544 13031>,
			<11798 15000 15295 12626 12496 12984>,
			<11332 15239 15690 12645 12488 12971>,
			<11222 13542 15522 13757 12780 12976>,
			<11164 11620 15346 14916 13346 12988>,
			<11147 11395 15735 15196 14488 13623>,
			<11138 11336 16710 15351 16212 15149>,
			<11142 11338 16781 15360 16636 15591>,
			<11208 11472 14855 15260 16144 15468>,
			<11297 11577 13420 15198 15609 15275>,
			<11387 11538 13412 15261 15310 14900>,
			<11471 11468 13412 15344 15064 14480>,
			<11478 11551 13468 15135 14814 14415>,
			<11437 12059 13722 14438 14551 14414>,
			<11413 12529 13881 14174 14451 14407>,
			<11447 12788 13910 14259 14469 14179>,
			<11507 13028 13935 14334 14490 13928>,
			<11554 13339 14005 14200 14385 14188>,
			<11600 13706 14127 13936 14111 14899>,
			<11652 14099 14255 13885 14043 15108>,
			<11729 14541 14414 13925 14224 14956>,
			<11781 14960 14505 13948 14364 14804>,
			<11777 15340 14293 13944 14205 14737>,
			<11761 15662 13937 13932 13938 14693>,
			<11708 15782 13893 13876 13956 14824>,
			<11506 15832 14003 13772 14200 15337>,
			<11304 15541 14240 13936 14180 14787>,
			<11113 14165 14446 14436 14108 13888>,
			<10974 11969 13821 15815 14451 15103>,
			<10947 11493 13117 16315 15662 14691>,
			<11059 11547 13244 15581 15606 15108>,
			<11029 11313 12797 16147 15657 14667>,
			<11015 11224 12123 15391 14319 14002>,
			<10971 11408 11930 14475 13846 13812>,
			<11032 11377 11930 14361 13852 14074>,
			<10826 11270 11902 13341 14431 15126>,
			<10122 10882 11885 14225 15840 15837>,
			<9648 10707 11777 14324 17238 17191>,
			<9315 10381 11861 15833 17137 17464>,
			<9315 10381 11861 15833 17137 17464>,
			<9315 10381 11861 15833 17137 17464>;
	};

	qcom,pc-temp-y6-lut {
		qcom,lut-col-legend = <(-10) 0 10 25 40 50>;
		qcom,lut-row-legend = <10000 9800 9600 9400 9200 9000>,
			<8800 8600 8400 8200 8000 7800>,
			<7600 7400 7200 7000 6800 6600>,
			<6400 6200 6000 5800 5600 5400>,
			<5200 5000 4800 4600 4400 4200>,
			<4000 3800 3600 3400 3200 3000>,
			<2800 2600 2400 2200 2000 1800>,
			<1600 1400 1200 1000 900 800>,
			<700 600 500 400 300 200>,
			<100 0>;
		qcom,lut-data = <7747 6352 5784 5350 5226 5196>,
			<7793 6503 5793 5342 5223 5197>,
			<7813 6593 5806 5338 5222 5198>,
			<7812 6638 5819 5339 5222 5199>,
			<7795 6654 5829 5342 5223 5200>,
			<7765 6653 5832 5346 5224 5202>,
			<7669 6603 5832 5357 5229 5203>,
			<7562 6547 5830 5365 5234 5204>,
			<7510 6538 5814 5362 5236 5206>,
			<7474 6533 5780 5355 5238 5208>,
			<7466 6535 5774 5355 5240 5210>,
			<7466 6556 5803 5370 5242 5213>,
			<7466 6575 5830 5385 5244 5217>,
			<7450 6581 5842 5390 5248 5220>,
			<7414 6584 5850 5396 5254 5224>,
			<7380 6579 5848 5405 5260 5229>,
			<7342 6552 5836 5420 5269 5235>,
			<7325 6518 5819 5430 5279 5244>,
			<7324 6472 5788 5437 5296 5258>,
			<7323 6435 5754 5440 5308 5268>,
			<7325 6438 5728 5420 5295 5258>,
			<7332 6456 5707 5374 5260 5229>,
			<7342 6475 5702 5355 5241 5213>,
			<7359 6498 5701 5347 5232 5206>,
			<7378 6523 5701 5343 5228 5203>,
			<7393 6547 5711 5342 5228 5203>,
			<7408 6573 5734 5341 5229 5204>,
			<7422 6600 5756 5343 5230 5205>,
			<7434 6629 5781 5350 5232 5208>,
			<7448 6659 5807 5359 5235 5211>,
			<7467 6691 5833 5371 5240 5215>,
			<7487 6725 5861 5386 5246 5219>,
			<7502 6764 5891 5400 5252 5224>,
			<7515 6808 5924 5414 5259 5231>,
			<7531 6853 5958 5428 5261 5232>,
			<7554 6901 5995 5443 5260 5226>,
			<7577 6947 6031 5456 5259 5221>,
			<7592 6992 6064 5466 5260 5221>,
			<7606 7032 6096 5476 5260 5222>,
			<7623 7058 6123 5488 5264 5226>,
			<7645 7075 6148 5502 5276 5236>,
			<7676 7080 6175 5523 5283 5236>,
			<7721 7081 6197 5534 5287 5235>,
			<7771 7071 6192 5495 5283 5235>,
			<7840 7099 6213 5521 5281 5230>,
			<8017 7196 6283 5563 5307 5253>,
			<8132 7248 6306 5592 5320 5261>,
			<8280 7309 6332 5601 5329 5268>,
			<8460 7396 6373 5603 5341 5277>,
			<8720 7485 6417 5608 5345 5283>,
			<9192 7586 6455 5593 5337 5280>,
			<10419 7736 6516 5614 5343 5284>,
			<12829 8002 6629 5656 5362 5301>,
			<16551 8793 6823 5759 5406 5345>,
			<16551 8793 6823 5759 5406 5345>,
			<16551 8793 6823 5759 5406 5345>;
	};
};
